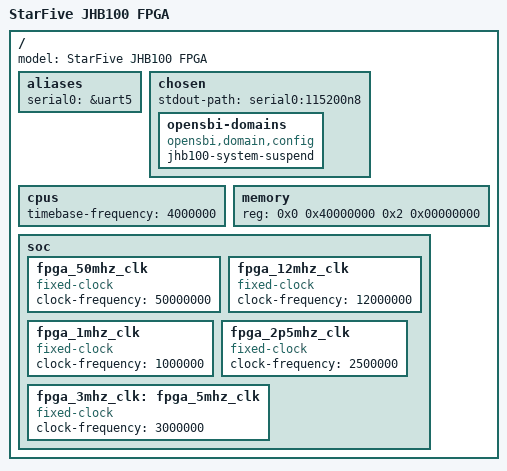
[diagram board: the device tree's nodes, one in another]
// SPDX-License-Identifier: GPL-2.0 OR MIT
/*
 * Copyright (c) 2021-2022 StarFive Technology Co., Ltd.
 */

#include "jhb100.dtsi"

/ {
	model = "StarFive JHB100 FPGA";

	aliases {
		serial0 = &uart5;
	};

	chosen {
		stdout-path = "serial0:115200n8";
		/* tick-timer = "timer0"; */

		opensbi-domains {
			compatible = "opensbi,domain,config";
			jhb100-system-suspend;
		};
	};

	cpus {
		timebase-frequency = <4000000>;

	};

	memory {
		device_type = "memory";
		reg = <0x0 0x40000000 0x2 0x00000000>; /* 8GB */
	};

	soc {

		fpga_50mhz_clk: fpga_50mhz_clk {
			compatible = "fixed-clock";
			#clock-cells = <0>;
			clock-frequency = <50000000>;
		};

		fpga_12mhz_clk: fpga_12mhz_clk {
			compatible = "fixed-clock";
			#clock-cells = <0>;
			clock-frequency = <12000000>;
		};

		fpga_1mhz_clk: fpga_1mhz_clk {
			compatible = "fixed-clock";
			#clock-cells = <0>;
			clock-frequency = <1000000>;
		};

		fpga_2p5mhz_clk: fpga_2p5mhz_clk {
			compatible = "fixed-clock";
			#clock-cells = <0>;
			clock-frequency = <2500000>;
		};

		fpga_3mhz_clk: fpga_5mhz_clk {
			compatible = "fixed-clock";
			#clock-cells = <0>;
			clock-frequency = <3000000>;
		};

	};
};
